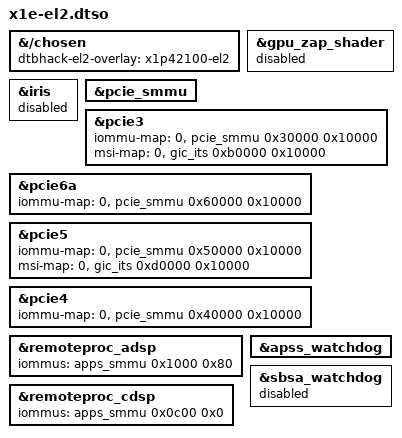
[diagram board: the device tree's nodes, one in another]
// SPDX-License-Identifier: BSD-3-Clause
/*
 * Qualcomm X1P42100 EL2 changes.
 *
 * The Qualcomm firmware normally starts UEFI/Linux in EL1.  When Secure
 * Launch hands EL2 to Linux, the PCIe SMMU must be owned by Linux and the
 * zap shader and SBSA watchdog must not be accessed by the EL2 kernel.
 * Keep this as an overlay so the normal EL1 DTB remains usable.
 *
 * The node labels match the upstream qcom x1-el2.dtso overlay.  They are
 * declared in the retained base DTS so fdtoverlay can resolve phandles rather
 * than relying on the numeric phandles of one particular decompiled DTB.
 */

/dts-v1/;
/plugin/;

&{/chosen} {
	dtbhack-el2-overlay = "x1p42100-el2";
};

&gpu_zap_shader {
	status = "disabled";
};

/* The video block is not usable until its EL2 firmware path is implemented. */
&iris {
	status = "disabled";
};

&pcie_smmu {
	status = "okay";
};

/* Give Linux the PCIe stream IDs used by every X1P PCIe controller. */
&pcie3 {
	iommu-map = <0 &pcie_smmu 0x30000 0x10000>;
	msi-map = <0 &gic_its 0xb0000 0x10000>;
};

&pcie6a {
	iommu-map = <0 &pcie_smmu 0x60000 0x10000>;
};

&pcie5 {
	iommu-map = <0 &pcie_smmu 0x50000 0x10000>;
	msi-map = <0 &gic_its 0xd0000 0x10000>;
};

&pcie4 {
	iommu-map = <0 &pcie_smmu 0x40000 0x10000>;
};

/* These coprocessors are owned by Linux only after the EL2 transition. */
&remoteproc_adsp {
	iommus = <&apps_smmu 0x1000 0x80>;
};

&remoteproc_cdsp {
	iommus = <&apps_smmu 0x0c00 0x0>;
};

/* The APSS watchdog is Linux-owned in EL2; the SBSA watchdog is not. */
&apss_watchdog {
	status = "okay";
};

&sbsa_watchdog {
	status = "disabled";
};
